# MCU_NAVSS0_UDMASS_UDMAP0_CFG_RFLOW register map
Vendor: Texas Instruments
Peripheral module from a debugger description file (folder am65x).
Registers are 32-bit, read-write, reset 0x0 unless marked. A register's access mark holds for its fields unless they carry their own. Offsets are as the file gives them; lines under a group give offsets from that group; [hi:lo] are bit positions; {n}, {i} and the like mark numbered series; 'fields as' and 'values as' point back to an identical list; <NAME> marks a mode.

## MCU_NAVSS0_UDMASS_UDMAP0_CFG_RFLOW
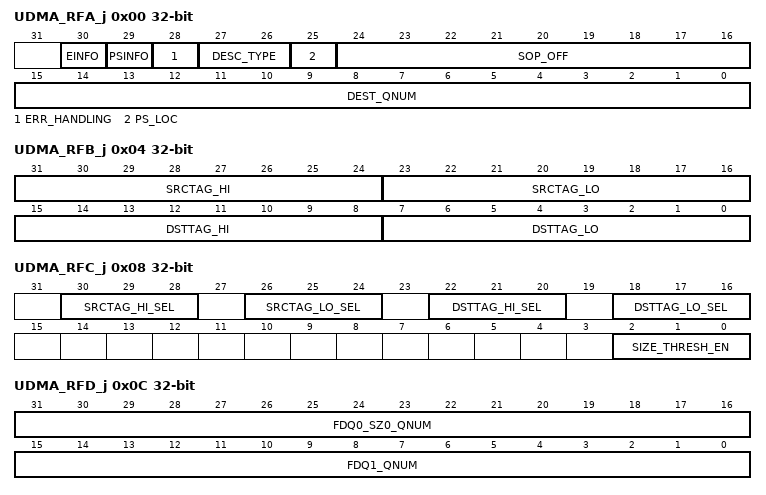
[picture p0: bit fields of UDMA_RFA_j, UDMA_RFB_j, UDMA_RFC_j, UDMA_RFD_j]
0x00 UDMA_RFA_j — The Rx Flow N Configuration Register A contains static configuration information for the Rx DMA flow. The fields in this register can only be changed when all of the DMA channels that use this flow have been disabled. The fields in this register are as follows: Offset = 0h + (j * 40h); where j = 0h to 12Bh for NAVSS0_UDMASS_UDMAP0_CFG_RFLOW j = 0h to 5Fh for MCU_NAVSS0_UDMASS_UDMAP0_CFG_RFLOW
  [30] EINFO — Rx Extended Packet Info Block Present: This bit controls whether or not the Extended Packet Info Block will be present in the Rx Packet Descriptor. If this bit is clear, the port DMA will clear the Extended Packet Info Present bit in the PD and will drop any Timestamp or SW Data words that are presented from the back end application. If this bit is set, the port DMA will set the Extended Packet Info Block Present bit in the PD and will copy any Timestamp or SW Data words that are presented across the Rx streaming interface into the Extended Packet Info Block words in the descriptor. If no Timestamp or SW Data words are presented from the back end application, the port DMA will overwrite the fields in the PD with zeroes.
  [29] PSINFO — Rx PS Words Present: This bit controls whether or not the Protocol Specific words will be present in the Rx Packet Descriptor. If this bit is clear, the port DMA will set the PS word count to 0 in the PD and will drop any PS words that are presented from the back end application. If this bit is set, the port DMA will set the PS word count to the value given by the back end application and will copy the PS words from the back end application to the location
  [28] ERR_HANDLING — Rx Error Handling Mode: This bit controls the error handling mode for the flow and is only used when channel errors (i.e. descriptor or buffer starvation occurs): 0 = Starvation errors result in dropping packet and reclaiming any used descriptor or buffer resources back to the original queues/pools they were allocated from 1 = Starvation errors result in subsequent re-try of the descriptor allocation operation. In this mode, the DMA will save it's internal operational state back to the internal state RAM without issuing an advance operation to it's internal FIFO buffers. This results in the DMA re-initiating the data transfer at a later time with the intention that additional free buffers and/or descriptors will have been added.
  [27:26] DESC_TYPE — Rx Descriptor Type: This field indicates the descriptor type to use: 0 = Host 1 = RESERVED 2 = Monolithic 3 = RESERVED
  [25] PS_LOC — Rx Protocol Specific Location: This bit controls where the Protocol Specific words will be placed in the Host Mode data structure. If this bit is cleared, the DMA will clear the Protocol Specific Region Location bit in the PD and will place the Protocol Specific Words at the end of the Packet Descriptor. If this bit is set, the DMA will set the Protocol Specific Region Location bit in the PD and will place the Protocol Specific Words at the beginning of the data buffer. When this mode is used, it is required that the resulting target data buffer pointer (which is calculated by adding the host_rx_sop_offset to the original buffer pointer in the Packet Descriptor) is aligned to a 32-bit boundary to avoid unwanted buffer truncation as the DMA will round up to the next 32-bit aligned boundary.
  [24:16] SOP_OFF — Rx Start of Packet Offset: This field specifies the number of bytes that are to be skipped in the SOP buffer before beginning to write the payload or protocol specific bytes(if they are in the sop buffer). This value must be less than the minimum size of a buffer in the system. Valid values are 0 - 255 bytes. Note that for monolithic packets the value of this field must always be initialized to be greater than or equal to 4 times the maximum number of protocol specific 32-bit words that are required by any of the packet types that will be transferred by this channel. This is important as the primary purpose of this field is to ensure that space is left in the descriptor to place the protocol specific information without overwriting or being overwritten by the Rx data. The secondary purpose of this field is to allow space to be left prior to the data in the descriptor in case header information needs to be added as the packet is passed thorough the system.
  [15:0] DEST_QNUM — Rx Destination Queue: This field indicates the default receive queue that packets on this flow should be placed onto.
0x04 UDMA_RFB_j — The Rx Flow N Configuration Register B contains static configuration information for the Rx DMA flow. The fields in this register can only be changed when all of the DMA channels that use this flow have been disabled. The fields in this register are as follows: Offset = 4h + (j * 40h); where j = 0h to 12Bh for NAVSS0_UDMASS_UDMAP0_CFG_RFLOW j = 0h to 5Fh for MCU_NAVSS0_UDMASS_UDMAP0_CFG_RFLOW
  [31:24] SRCTAG_HI — Rx Source Tag High Byte Constant Value: This is the value to insert into bits 15:8 of the source tag if the rx_src_tag_hi_sel is set to 1.
  [23:16] SRCTAG_LO — Rx Source Tag Low Byte Constant Value: This is the value to insert into bits 7:0 of the source tag if the rx_src_tag_lo_sel is set to 1.
  [15:8] DSTTAG_HI — Rx Destination Tag High Byte Constant Value: This is the value to insert into bits 15:8 of the destination tag if the rx_dest_tag_hi_sel is set to 1.
  [7:0] DSTTAG_LO — Rx Destination Tag Low Byte Constant Value: This is the value to insert into bits 7:0 of the destination tag if the rx_dest_tag_lo_sel is set to 1.
0x08 UDMA_RFC_j — The Rx Flow N Configuration Register C contains static configuration information for the Rx DMA flow. The fields in this register can only be changed when all of the DMA channels that use this flow have been disabled. The fields in this register are as follows: Offset = 8h + (j * 40h); where j = 0h to 12Bh for NAVSS0_UDMASS_UDMAP0_CFG_RFLOW j = 0h to 5Fh for MCU_NAVSS0_UDMASS_UDMAP0_CFG_RFLOW
  [30:28] SRCTAG_HI_SEL — Rx Source Tag Low Byte Selector: This field specifies the source for bits 7:0 of the source tag field in Word 3 of the output Packet Descriptor. This field is encoded as follows: 0 = do not overwrite 1 = overwrite with value given in rx_src_tag_hi 2 = overwrite with flow_id[7:0] from back end application 3 = RESERVED 4 = overwrite with src_tag[7:0] from back end application 5-7 = RESERVED
  [26:24] SRCTAG_LO_SEL — Rx Source Tag Low Byte Selector: This field specifies the source for bits 7:0 of the source tag field in Word 3 of the output Packet Descriptor. This field is encoded as follows: 0 = do not overwrite 1 = overwrite with value given in rx_src_tag_lo 2 = overwrite with flow_id[7:0] from back end application 3 = RESERVED 4 = overwrite with src_tag[7:0] from back end application 5-7 = RESERVED
  [22:20] DSTTAG_HI_SEL — Rx Destination Tag High Byte Selector: This field specifies the source for bits 15:8 of the destination tag field in the word 3 of the output Packet Descriptor. This field is encoded as follows: 0 = do not overwrite 1 = overwrite with value given in rx_dest_tag_hi 2 = overwrite with flow_id[7:0] from back end application 3 = RESERVED 4 = overwrite with dest_tag[7:0] from back end application 5 = overwrite with dest_tag[15:8] from back end application 6-7 = RESERVED
  [18:16] DSTTAG_LO_SEL — Rx Destination Tag Low Byte Selector: This field specifies the source for bits 7:0 of the destination tag field in word 3 of the output Packet Descriptor. This field is encoded as follows: 0 = do not overwrite 1 = overwrite with value given in rx_dest_tag_lo 2 = overwrite with flow_id[7:0] from back end application 3 = RESERVED 4 = overwrite with dest_tag[7:0] from back end application 5 = overwrite with dest_tag[15:8] from back end application 6-7 = RESERVED
  [2:0] SIZE_THRESH_EN — Rx Packet Sized Based Free Buffer Queue Enables: These bits control whether or not the flow will compare the packet size received from the back end application against the rx_size_threshN fields to determine which FDQ to allocate the SOP buffer from. Each bit in this field corresponds to 1 of the 3 potential size thresholds that can be compared against. Bit 0 corresponds to rx_size_thresh0 and bit 2 corresponds to rx_size_thresh2. The bits in this field is encoded as follows: 0 = Do not use the threshold. 1 = Use the thresholds to select between the 4 different potential SOP FDQs. If none of the thresholds are enabled, the DMA controller in the port will allocate the SOP buffer from the queue specified by the rx_fdq0_sz0_qnum field. Support for packet size based FDQ selection is OPTIONAL. If the port does not implement this feature, the bits of this field will be hardcoded to 0 and will not be writable by the host.
0x0C UDMA_RFD_j — The Rx Flow N Configuration Register D contains static configuration information for the Rx DMA flow. The fields in this register can only be changed when all of the DMA channels that use this flow have been disabled. The fields in this register are as follows: Offset = Ch + (j * 40h); where j = 0h to 12Bh for NAVSS0_UDMASS_UDMAP0_CFG_RFLOW j = 0h to 5Fh for MCU_NAVSS0_UDMASS_UDMAP0_CFG_RFLOW
  [31:16] FDQ0_SZ0_QNUM — Rx Free Descriptor 0 Queue Index - Size 0: This field specifies which Free Descriptor Queue should be used for the 1st Rx buffer in a packet whose size is less than or equal to the rx_size0 value.
  [15:0] FDQ1_QNUM — Rx Free Descriptor 1 Queue Index: This field specifies which Free Descriptor Queue should be used for the 2nd Rx buffer in a host type packet
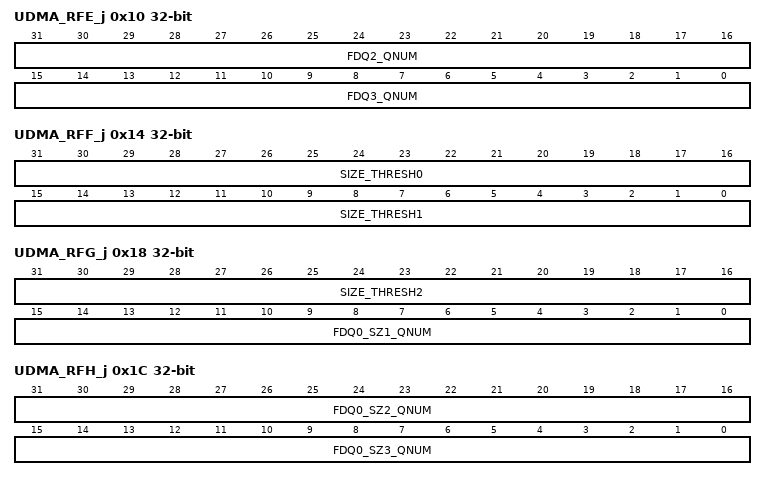
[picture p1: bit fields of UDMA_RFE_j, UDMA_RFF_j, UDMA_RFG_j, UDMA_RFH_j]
0x10 UDMA_RFE_j — The Rx Flow N Configuration Register E contains static configuration information for the Rx DMA flow. The fields in this register can only be changed when all of the DMA channels that use this flow have been disabled. The fields in this register are as follows: Offset = 10h + (j * 40h); where j = 0h to 12Bh for NAVSS0_UDMASS_UDMAP0_CFG_RFLOW j = 0h to 5Fh for MCU_NAVSS0_UDMASS_UDMAP0_CFG_RFLOW
  [31:16] FDQ2_QNUM — Rx Free Descriptor 2 Queue Index: This field specifies which Free Descriptor Queue should be used for the 3rd Rx buffer in a host type packet
  [15:0] FDQ3_QNUM — Rx Free Descriptor 3 Queue Index: This field specifies which Free Descriptor Queue should be used for the 4th or later Rx buffers in a host type packet
0x14 UDMA_RFF_j — The Rx Flow N Configuration Register F contains static configuration information for the Rx DMA flow. The fields in this register can only be changed when all of the DMA channels that use this flow have been disabled. This register is OPTIONAL. The fields in this register are as follows: Offset = 14h + (j * 40h); where j = 0h to 12Bh for NAVSS0_UDMASS_UDMAP0_CFG_RFLOW j = 0h to 5Fh for MCU_NAVSS0_UDMASS_UDMAP0_CFG_RFLOW
  [31:16] SIZE_THRESH0 — Rx Packet Size Threshold 0: This value is left shifted by 5 bits and compared against the packet size to determine which free descriptor queue should be used for the SOP buffer in the packet. If the packet size is less than or equal to the value given in this threshold, the DMA controller in the port will allocate the SOP buffer from the queue given by the rx_fdq0_sz0_qnum field. This field is OPTIONAL.
  [15:0] SIZE_THRESH1 — Rx Packet Size Threshold 1: This value is left shifted by 5 bits and compared against the packet size to determine which free descriptor queue should be used for the SOP buffer in the packet. If the packet size is greater than the rx_size_thresh0 but is less than or equal to the value given in this threshold, the DMA controller in the port will allocate the SOP buffer from the queue given by the rx_fdq0_sz1_qnum field. If enabled, this value must be greater than the value given in the rx_size_thresh0 field. This field is optional.
0x18 UDMA_RFG_j — The Rx Flow N Configuration Register G contains static configuration information for the Rx DMA flow. The fields in this register can only be changed when all of the DMA channels that use this flow have been disabled. This register is OPTIONAL. The fields in this register are as follows: Offset = 18h + (j * 40h); where j = 0h to 12Bh for NAVSS0_UDMASS_UDMAP0_CFG_RFLOW j = 0h to 5Fh for MCU_NAVSS0_UDMASS_UDMAP0_CFG_RFLOW
  [31:16] SIZE_THRESH2 — Rx Packet Size Threshold 2: This value is left shifted by 5 bits and compared against the packet size to determine which free descriptor queue should be used for the SOP buffer in the packet. If the packet size is less than or equal to the value given in this threshold, the DMA controller in the port will allocate the SOP buffer from the queue given by the rx_fdq0_sz2_qnum field. If enabled, this value must be greater than the value given in the rx_size_thresh1 field. This field is optional.
  [15:0] FDQ0_SZ1_QNUM — Rx Free Descriptor 0 Queue Index - Size 1: This field specifies which Free Descriptor Queue should be used for the 1st Rx buffer in a packet whose size is less than or equal to the rx_size0 value. This field is optional.
0x1C UDMA_RFH_j — The Rx Flow N Configuration Register H contains static configuration information for the Rx DMA flow. The fields in this register can only be changed when all of the DMA channels that use this flow have been disabled. This register is OPTIONAL. The fields in this register are as follows: Offset = 1Ch + (j * 40h); where j = 0h to 12Bh for NAVSS0_UDMASS_UDMAP0_CFG_RFLOW j = 0h to 5Fh for MCU_NAVSS0_UDMASS_UDMAP0_CFG_RFLOW
  [31:16] FDQ0_SZ2_QNUM — Rx Free Descriptor 0 Queue Index - Size 2: This field specifies which Free Descriptor Queue should be used for the 1st Rx buffer in a packet whose size is less than or equal to the rx_size1 value. This field is optional.
  [15:0] FDQ0_SZ3_QNUM — Rx Free Descriptor 0 Queue Index - Size 3: This field specifies which Free Descriptor Queue should be used for the 1st Rx buffer in a packet whose size is less than or equal to the rx_size2 value. This field is optional.
